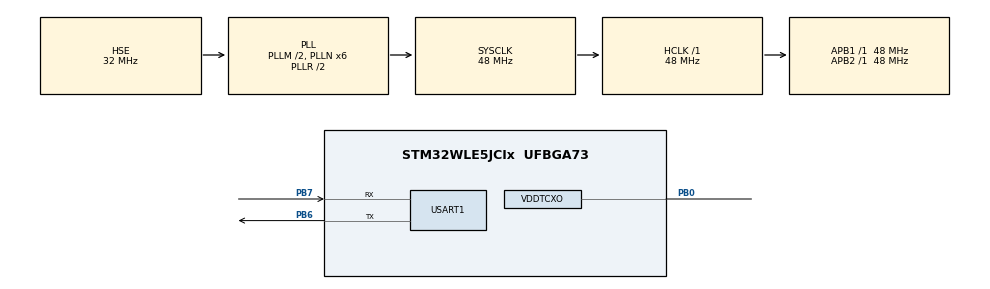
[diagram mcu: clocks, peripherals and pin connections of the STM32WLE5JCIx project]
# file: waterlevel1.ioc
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Mcu.Family=STM32WL
Mcu.Name=STM32WLE5JCIx
Mcu.Package=UFBGA73
NVIC.PriorityGroup=NVIC_PRIORITYGROUP_4
OSC_IN.Mode=HSE-TCXO
OSC_IN.Signal=RCC_OSC_IN
PB0-VDD_TCXO.Mode=HSE-TCXO
PB0-VDD_TCXO.Signal=VDDTCXO
PB6.Mode=Asynchronous
PB6.Signal=USART1_TX
PB7.Mode=Asynchronous
PB7.Signal=USART1_RX
ProjectManager.HeapSize=0x200
ProjectManager.StackSize=0x400
ProjectManager.TargetToolchain=STM32CubeIDE
RCC.AHBCLKDivider=RCC_SYSCLK_DIV1
RCC.AHBFreq_Value=48000000
RCC.APB1Freq_Value=48000000
RCC.APB1TimFreq_Value=48000000
RCC.APB2Freq_Value=48000000
RCC.APB2TimFreq_Value=48000000
RCC.APB3Freq_Value=48000000
RCC.CortexFreq_Value=48000000
RCC.HCLKFreq_Value=48000000
RCC.HSE_VALUE=32000000
RCC.HSI_VALUE=16000000
RCC.LSE_VALUE=32768
RCC.PLLM=RCC_PLLM_DIV2
RCC.PLLN=6
RCC.PLLR=RCC_PLLR_DIV2
RCC.PLLSourceVirtual=RCC_PLLSOURCE_HSE
RCC.SYSCLKFreq_VALUE=48000000
RCC.SYSCLKSource=RCC_SYSCLKSOURCE_PLLCLK
RCC.VCOOutputFreq_Value=96000000
USART1.VirtualMode-Asynchronous=VM_ASYNC
board=custom

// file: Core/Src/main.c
/* USER CODE BEGIN Header */
/**
  ******************************************************************************
  * @file           : main.c
  * @brief          : Main program body
  ******************************************************************************
  * @attention
  *
  * Copyright (c) 2026 STMicroelectronics.
  * All rights reserved.
  *
  * This software is licensed under terms that can be found in the LICENSE file
  * in the root directory of this software component.
  * If no LICENSE file comes with this software, it is provided AS-IS.
  *
  ******************************************************************************
  */
/* USER CODE END Header */
#include "main.h"

#include "app_x-cube-ai.h"

UART_HandleTypeDef huart1;

void SystemClock_Config(void);
static void MX_GPIO_Init(void);
static void MX_USART1_UART_Init(void);

int main(void)
{

  /* MCU Configuration--------------------------------------------------------*/

  /* Reset of all peripherals, Initializes the Flash interface and the Systick. */
  HAL_Init();

  /* Configure the system clock */
  SystemClock_Config();

  /* Initialize all configured peripherals */
  MX_GPIO_Init();
  MX_USART1_UART_Init();
STM32CubeAI_Studio_AI_Init();

  /* Infinite loop */
  /* USER CODE BEGIN WHILE */
  while (1)
  {
STM32CubeAI_Studio_AI_Process();
    /* USER CODE END WHILE */

  }
}

void SystemClock_Config(void)
{
  RCC_OscInitTypeDef RCC_OscInitStruct = {0};
  RCC_ClkInitTypeDef RCC_ClkInitStruct = {0};

  /** Configure the main internal regulator output voltage
  */
  __HAL_PWR_VOLTAGESCALING_CONFIG(PWR_REGULATOR_VOLTAGE_SCALE1);

  /** Initializes the CPU, AHB and APB buses clocks
  */
  RCC_OscInitStruct.OscillatorType = RCC_OSCILLATORTYPE_HSE;
  RCC_OscInitStruct.HSEState = RCC_HSE_BYPASS_PWR;
  RCC_OscInitStruct.HSEDiv = RCC_HSE_DIV1;
  RCC_OscInitStruct.PLL.PLLState = RCC_PLL_ON;
  RCC_OscInitStruct.PLL.PLLSource = RCC_PLLSOURCE_HSE;
  RCC_OscInitStruct.PLL.PLLM = RCC_PLLM_DIV2;
  RCC_OscInitStruct.PLL.PLLN = 6;
  RCC_OscInitStruct.PLL.PLLP = RCC_PLLP_DIV2;
  RCC_OscInitStruct.PLL.PLLR = RCC_PLLR_DIV2;
  RCC_OscInitStruct.PLL.PLLQ = RCC_PLLQ_DIV2;
  if (HAL_RCC_OscConfig(&RCC_OscInitStruct) != HAL_OK)
  {
    Error_Handler();
  }

  /** Configure the SYSCLKSource, HCLK, PCLK1 and PCLK2 clocks dividers
  */
  RCC_ClkInitStruct.ClockType = RCC_CLOCKTYPE_HCLK3|RCC_CLOCKTYPE_HCLK
                              |RCC_CLOCKTYPE_SYSCLK|RCC_CLOCKTYPE_PCLK1
                              |RCC_CLOCKTYPE_PCLK2;
  RCC_ClkInitStruct.SYSCLKSource = RCC_SYSCLKSOURCE_PLLCLK;
  RCC_ClkInitStruct.AHBCLKDivider = RCC_SYSCLK_DIV1;
  RCC_ClkInitStruct.APB1CLKDivider = RCC_HCLK_DIV1;
  RCC_ClkInitStruct.APB2CLKDivider = RCC_HCLK_DIV1;
  RCC_ClkInitStruct.AHBCLK3Divider = RCC_SYSCLK_DIV1;

  if (HAL_RCC_ClockConfig(&RCC_ClkInitStruct, FLASH_LATENCY_2) != HAL_OK)
  {
    Error_Handler();
  }
}

static void MX_USART1_UART_Init(void)
{

  huart1.Instance = USART1;
  huart1.Init.BaudRate = 115200;
  huart1.Init.WordLength = UART_WORDLENGTH_8B;
  huart1.Init.StopBits = UART_STOPBITS_1;
  huart1.Init.Parity = UART_PARITY_NONE;
  huart1.Init.Mode = UART_MODE_TX_RX;
  huart1.Init.HwFlowCtl = UART_HWCONTROL_NONE;
  huart1.Init.OverSampling = UART_OVERSAMPLING_16;
  huart1.Init.OneBitSampling = UART_ONE_BIT_SAMPLE_DISABLE;
  huart1.Init.ClockPrescaler = UART_PRESCALER_DIV1;
  huart1.AdvancedInit.AdvFeatureInit = UART_ADVFEATURE_NO_INIT;
  if (HAL_UART_Init(&huart1) != HAL_OK)
  {
    Error_Handler();
  }
  if (HAL_UARTEx_SetTxFifoThreshold(&huart1, UART_TXFIFO_THRESHOLD_1_8) != HAL_OK)
  {
    Error_Handler();
  }
  if (HAL_UARTEx_SetRxFifoThreshold(&huart1, UART_RXFIFO_THRESHOLD_1_8) != HAL_OK)
  {
    Error_Handler();
  }
  if (HAL_UARTEx_DisableFifoMode(&huart1) != HAL_OK)
  {
    Error_Handler();
  }

}

static void MX_GPIO_Init(void)
{

  /* GPIO Ports Clock Enable */
  __HAL_RCC_GPIOB_CLK_ENABLE();

}

void Error_Handler(void)
{
  __disable_irq();
  while (1)
  {
  }
}
